# S32R372 register map
Vendor: Freescale Semiconductor, Inc.; Series: Qorivva; File version: 1.6
Registers are 32-bit, read-write, reset 0x0 unless marked. A register's access mark holds for its fields unless they carry their own. Offsets are from the block's base; [hi:lo] are bit positions; {n}, {i} and the like mark numbered series; 'fields as' and 'values as' point back to an identical list.

## AXBS_0 — Crossbar switch
Base 0xFC004000; register names take the prefix AXBS_0_
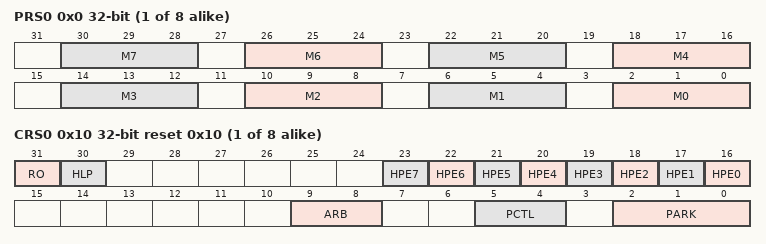
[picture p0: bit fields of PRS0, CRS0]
{0x0+0x100*i} PRS{i} (i=0..7) — Priority Registers Slave
  [all] fields
    0=This master has level 1, or highest, priority when accessing the slave port; {v}=This master has level {v+1} priority when accessing the slave port (v=1..6); 7=This master has level 8, or lowest, priority when accessing the slave port
  [4n+2:4n] M{n} (n=0..7) — Master {n} Priority. Sets the arbitration priority for this port on the associated slave port.
{0x10+0x100*i} CRS{i} (i=0..7) reset 0x10 — Control Register
  [31] RO — Read Only
    0=The CRSn and PRSn registers are writeable; 1=The CRSn and PRSn registers are read-only and cannot be written (attempted writes have no effect on the registers and result in a bus error response)
  [30] HLP — Halt Low Priority
    0=The low power mode request has the highest priority for arbitration on this slave port; 1=The low power mode request has the lowest initial priority for arbitration on this slave port
  [n+16] HPE{n} (n=0..7) — On this slave port, enable priority elevation for master {n}
    0=Priority elevation for master {n} is disabled on this slave port; 1=Priority elevation for master {n} is enabled on this slave port
  [9:8] ARB — Arbitration Mode
    0=Fixed priority; 1=Round-robin (rotating) priority
  [5:4] PCTL — Parking Control
    0=When no master makes a request, the arbiter parks the slave port on the master port defined by the PARK bit field; 1=When no master makes a request, the arbiter parks the slave port on the last master to be in control of the slave port; 2=Low-power park. When no master makes a request, the slave port is not parked on a master and the arbiter drives all outputs to a constant safe state
  [2:0] PARK
    {v}=Park on master port M{v} (v=0..7)

## AXBS_1 — Crossbar switch
Base 0xFC008000; register names take the prefix AXBS_1_
Registers as AXBS_0.

## PRAM_XBAR
Base 0xFC00C000; register names take the prefix PRAM_XBAR_
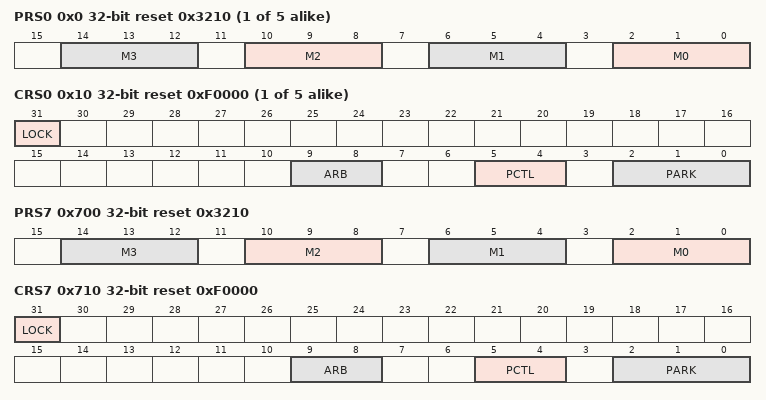
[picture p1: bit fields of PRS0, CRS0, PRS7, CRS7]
{0x0+0x100*i} PRS{i} (i=0..4) reset 0x3210 — Priority Register Slave
  [all] fields
    0=This master has level 1, or highest, priority when accessing the slave port; 1=This master has level 2 priority when accessing the slave port; 2=This master has level 3 priority when accessing the slave port; 3=This master has level 4 priority when accessing the slave port
  [4n+2:4n] M{n} (n=0..3) — Master {n} Priority
{0x10+0x100*i} CRS{i} (i=0..4) reset 0xF0000 — Control Register
  [31] LOCK — Locks the slave port's CRSn and PRSn registers to be read-only. After set, only a hardware reset clears it.
    0=The slave port's registers are writeable; 1=The slave port's registers are read-only and cannot be written. Attempted writes have no effect on the registers and result in a bus error response.
  [9:8] ARB — Arbitration Mode
    0=Fixed priority; 1=Round-robin, or rotating, priority
  [5:4] PCTL — Parking Control
    0=When no master makes a request, the arbiter parks the slave port on the master port defined by the PARK field; 1=When no master makes a request, the arbiter parks the slave port on the last master to be in control of the slave port; 2=When no master makes a request, the slave port is not parked on a master and the arbiter drives all outputs to a constant safe state
  [2:0] PARK
    {v}=Park on master port M{v} (v=0..3)
0x700 PRS7 reset 0x3210 — Priority Register Slave 7
  fields as PRS0
0x710 CRS7 reset 0xF0000 — Control Register 7
  fields as CRS0

## SMPU_0 — Memory protection unit
Base 0xFC010000; register names take the prefix SMPU_0_
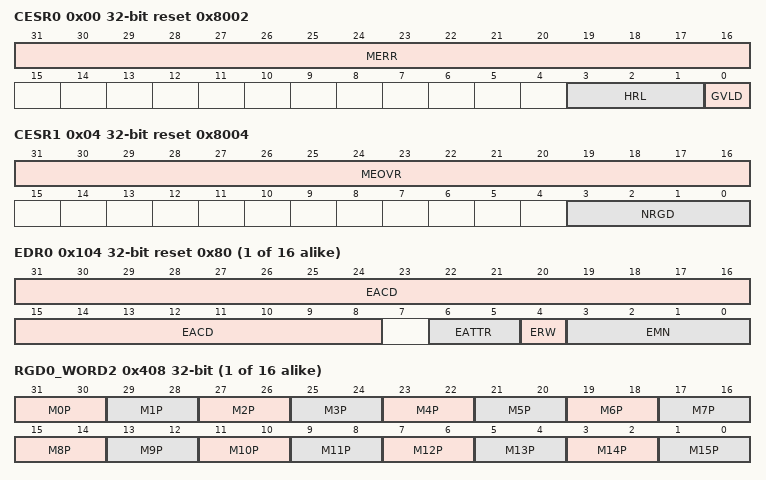
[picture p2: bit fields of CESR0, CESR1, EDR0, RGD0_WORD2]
0x00 CESR0 reset 0x8002 — Control/Error Status Register 0
  [31:16] MERR — Master n error, where the bus master number matches the bit number
    0=No error has occurred for bus master n; 1=An error has occurred for bus master n
  [3:1] HRL ro — Hardware revision level
  [0] GVLD — Global Valid (global enable/disable for the SMPU)
    0=SMPU is disabled. All accesses from all bus masters are allowed.; 1=SMPU is enabled
0x04 CESR1 ro reset 0x8004 — Control/Error Status Register 1
  [31:16] MEOVR — Master n error overrun, where the bus master number matches the bit number
    0=No error overrun condition has been detected for bus master n; 1=An error overrun condition has been detected for bus master n
  [3:0] NRGD — Number of region descriptors
    1=4 region descriptors; 2=8 region descriptors; 3=12 region descriptors; 4=16 region descriptors; 5=20 region descriptors; 6=24 region descriptors
{0x100+8i} EAR{i} (i=0..15) ro — Error Address Register, Bus Master n
  [31:0] EADDR — Error address
{0x104+8i} EDR{i} (i=0..15) ro reset 0x80 — Error Detail Register, Bus Master n
  [31:8] EACD — Error access control detail
  [6:5] EATTR — Error attributes
    0=User mode, instruction access; 1=User mode, data access; 2=Supervisor mode, instruction access; 3=Supervisor mode, data access
  [4] ERW — Error read/write
    0=Read; 1=Write
  [3:0] EMN — Error master number
{0x400+0x10*i} RGD{i}_WORD0 (i=0..15) — Region Descriptor n, Word 0
  [31:0] SRTADDR — Start address
{0x404+0x10*i} RGD{i}_WORD1 (i=0..15) — Region Descriptor n, Word 1
  [31:0] ENDADDR — End address
{0x408+0x10*i} RGD{i}_WORD2 (i=0..15) — Region Descriptor n, Word 2
  [31-2n:30-2n] M{n}P (n=0..15) — Bus master {n} permissions
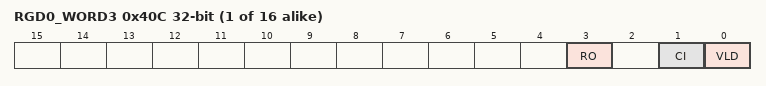
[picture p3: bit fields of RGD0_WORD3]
{0x40C+0x10*i} RGD{i}_WORD3 (i=0..15) — Region Descriptor n, Word 3
  [3] RO — Read-Only
    0=The region descriptor can be read or written; 1=Attempted writes to any location in the region descriptor are ignored with an error-free data transfer termination
  [1] CI — Cache Inhibit
    0=References to this region can be cached; 1=References to this region cannot be cached
  [0] VLD — Valid
    0=Region descriptor is invalid; 1=Region descriptor is valid

## SMPU_1 — Memory protection unit
Base 0xFC014000; register names take the prefix SMPU_1_
Registers as SMPU_0.
